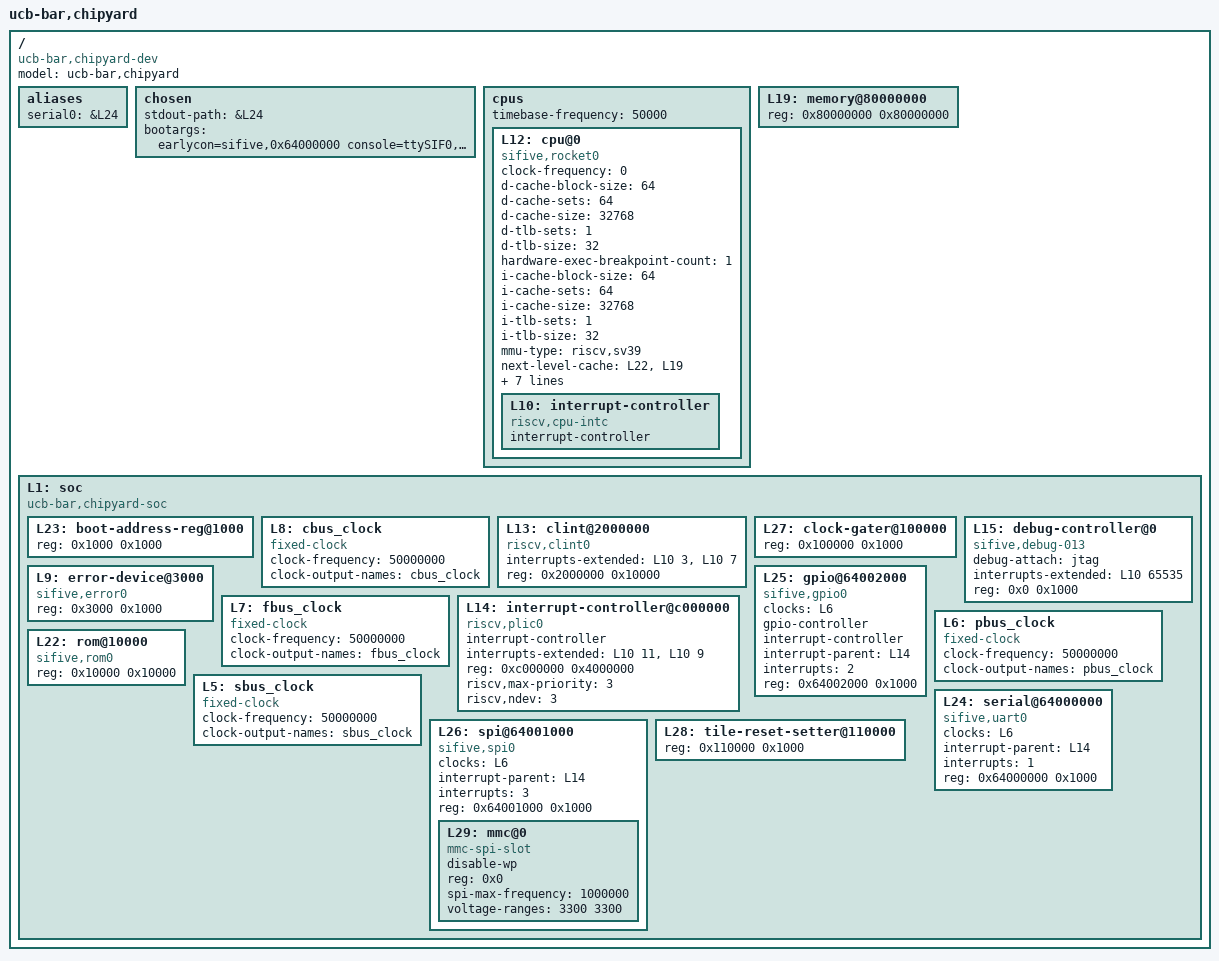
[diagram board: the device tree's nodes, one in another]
/dts-v1/;

/ {
	#address-cells = <1>;
	#size-cells = <1>;
	compatible = "ucb-bar,chipyard-dev";
	model = "ucb-bar,chipyard";

	aliases {
		serial0 = &L24;
	};

	chosen {
		stdout-path = &L24;
		bootargs = "earlycon=sifive,0x64000000 console=ttySIF0,115200n8 init=/init loglevel=8";
	};

	cpus {
		#address-cells = <1>;
		#size-cells = <0>;
		timebase-frequency = <50000>;

		L12: cpu@0 {
			clock-frequency = <0>;
			compatible = "sifive,rocket0", "riscv";
			d-cache-block-size = <64>;
			d-cache-sets = <64>;
			d-cache-size = <32768>;
			d-tlb-sets = <1>;
			d-tlb-size = <32>;
			device_type = "cpu";
			hardware-exec-breakpoint-count = <1>;
			i-cache-block-size = <64>;
			i-cache-sets = <64>;
			i-cache-size = <32768>;
			i-tlb-sets = <1>;
			i-tlb-size = <32>;
			mmu-type = "riscv,sv39";
			next-level-cache = <&L22 &L19>;
			reg = <0x0>;
			riscv,isa = "rv64imafdczicsr_zifencei_zihpm_zfh_xrocket";
			riscv,pmpgranularity = <4>;
			riscv,pmpregions = <8>;
			status = "okay";
			timebase-frequency = <50000>;
			tlb-split;

			L10: interrupt-controller {
				#interrupt-cells = <1>;
				compatible = "riscv,cpu-intc";
				interrupt-controller;
			};
		};
	};

	L19: memory@80000000 {
		device_type = "memory";
		reg = <0x80000000 0x80000000>;
	};

	L1: soc {
		#address-cells = <1>;
		#size-cells = <1>;
		compatible = "ucb-bar,chipyard-soc", "simple-bus";
		ranges;

		L23: boot-address-reg@1000 {
			reg = <0x1000 0x1000>;
			reg-names = "control";
		};

		L8: cbus_clock {
			#clock-cells = <0>;
			clock-frequency = <50000000>;
			clock-output-names = "cbus_clock";
			compatible = "fixed-clock";
		};

		L13: clint@2000000 {
			compatible = "riscv,clint0";
			interrupts-extended = <&L10 3 &L10 7>;
			reg = <0x2000000 0x10000>;
			reg-names = "control";
		};

		L27: clock-gater@100000 {
			reg = <0x100000 0x1000>;
			reg-names = "control";
		};

		L15: debug-controller@0 {
			compatible = "sifive,debug-013", "riscv,debug-013";
			debug-attach = "jtag";
			interrupts-extended = <&L10 65535>;
			reg = <0x0 0x1000>;
			reg-names = "control";
		};

		L9: error-device@3000 {
			compatible = "sifive,error0";
			reg = <0x3000 0x1000>;
		};

		L7: fbus_clock {
			#clock-cells = <0>;
			clock-frequency = <50000000>;
			clock-output-names = "fbus_clock";
			compatible = "fixed-clock";
		};

		L25: gpio@64002000 {
			#gpio-cells = <2>;
			#interrupt-cells = <2>;
			clocks = <&L6>;
			compatible = "sifive,gpio0", "sifive,gpio1";
			gpio-controller;
			interrupt-controller;
			interrupt-parent = <&L14>;
			interrupts = <2>;
			reg = <0x64002000 0x1000>;
			reg-names = "control";
		};

		L14: interrupt-controller@c000000 {
			#interrupt-cells = <1>;
			compatible = "riscv,plic0";
			interrupt-controller;
			interrupts-extended = <&L10 11 &L10 9>;
			reg = <0xc000000 0x4000000>;
			reg-names = "control";
			riscv,max-priority = <3>;
			riscv,ndev = <3>;
		};

		L6: pbus_clock {
			#clock-cells = <0>;
			clock-frequency = <50000000>;
			clock-output-names = "pbus_clock";
			compatible = "fixed-clock";
		};

		L22: rom@10000 {
			compatible = "sifive,rom0";
			reg = <0x10000 0x10000>;
			reg-names = "mem";
		};

		L5: sbus_clock {
			#clock-cells = <0>;
			clock-frequency = <50000000>;
			clock-output-names = "sbus_clock";
			compatible = "fixed-clock";
		};

		L24: serial@64000000 {
			clocks = <&L6>;
			compatible = "sifive,uart0";
			interrupt-parent = <&L14>;
			interrupts = <1>;
			reg = <0x64000000 0x1000>;
			reg-names = "control";
		};

		L26: spi@64001000 {
			#address-cells = <1>;
			#size-cells = <0>;
			clocks = <&L6>;
			compatible = "sifive,spi0";
			interrupt-parent = <&L14>;
			interrupts = <3>;
			reg = <0x64001000 0x1000>;
			reg-names = "control";

			L29: mmc@0 {
				compatible = "mmc-spi-slot";
				disable-wp;
				reg = <0x0>;
				spi-max-frequency = <1000000>;
				voltage-ranges = <3300 3300>;
			};
		};

		L28: tile-reset-setter@110000 {
			reg = <0x110000 0x1000>;
			reg-names = "control";
		};
	};
};
